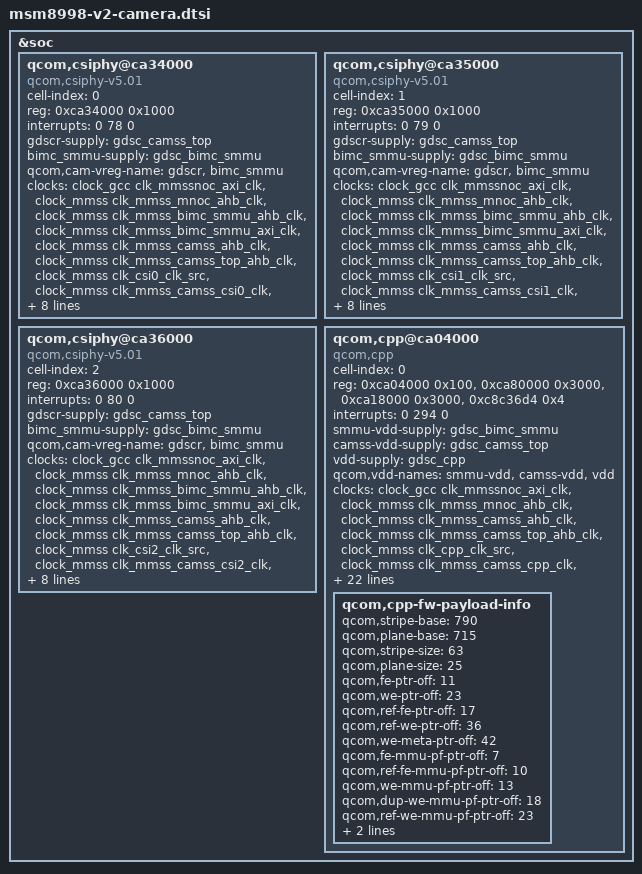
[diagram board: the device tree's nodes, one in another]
/*
 * Copyright (c) 2016, The Linux Foundation. All rights reserved.
 *
 * This program is free software; you can redistribute it and/or modify
 * it under the terms of the GNU General Public License version 2 and
 * only version 2 as published by the Free Software Foundation.
 *
 * This program is distributed in the hope that it will be useful,
 * but WITHOUT ANY WARRANTY; without even the implied warranty of
 * MERCHANTABILITY or FITNESS FOR A PARTICULAR PURPOSE.  See the
 * GNU General Public License for more details.
 */

&soc {
	qcom,csiphy@ca34000 {
		cell-index = <0>;
		compatible = "qcom,csiphy-v5.01", "qcom,csiphy";
		reg = <0xca34000 0x1000>;
		reg-names = "csiphy";
		interrupts = <0 78 0>;
		interrupt-names = "csiphy";
		gdscr-supply = <&gdsc_camss_top>;
		bimc_smmu-supply = <&gdsc_bimc_smmu>;
		qcom,cam-vreg-name = "gdscr", "bimc_smmu";
		clocks = <&clock_gcc clk_mmssnoc_axi_clk>,
			<&clock_mmss clk_mmss_mnoc_ahb_clk>,
			<&clock_mmss clk_mmss_bimc_smmu_ahb_clk>,
			<&clock_mmss clk_mmss_bimc_smmu_axi_clk>,
			<&clock_mmss clk_mmss_camss_ahb_clk>,
			<&clock_mmss clk_mmss_camss_top_ahb_clk>,
			<&clock_mmss clk_csi0_clk_src>,
			<&clock_mmss clk_mmss_camss_csi0_clk>,
			<&clock_mmss clk_mmss_camss_cphy_csid0_clk>,
			<&clock_mmss clk_csi0phytimer_clk_src>,
			<&clock_mmss clk_mmss_camss_csi0phytimer_clk>,
			<&clock_mmss clk_mmss_camss_ispif_ahb_clk>,
			<&clock_mmss clk_csiphy_clk_src>,
			<&clock_mmss clk_mmss_camss_csiphy0_clk>;
		clock-names = "mmssnoc_axi", "mnoc_ahb",
			"bmic_smmu_ahb", "bmic_smmu_axi",
			"camss_ahb_clk", "camss_top_ahb_clk",
			"csi_src_clk", "csi_clk", "cphy_csid_clk",
			"csiphy_timer_src_clk", "csiphy_timer_clk",
			"camss_ispif_ahb_clk", "csiphy_clk_src", "csiphy_clk";
		qcom,clock-rates = <0 0 0 0 0 0 256000000 0 0 200000000 0
			0 256000000 0>;
		status = "ok";
	};

	qcom,csiphy@ca35000 {
		cell-index = <1>;
		compatible = "qcom,csiphy-v5.01", "qcom,csiphy";
		reg = <0xca35000 0x1000>;
		reg-names = "csiphy";
		interrupts = <0 79 0>;
		interrupt-names = "csiphy";
		gdscr-supply = <&gdsc_camss_top>;
		bimc_smmu-supply = <&gdsc_bimc_smmu>;
		qcom,cam-vreg-name = "gdscr", "bimc_smmu";
		clocks = <&clock_gcc clk_mmssnoc_axi_clk>,
			<&clock_mmss clk_mmss_mnoc_ahb_clk>,
			<&clock_mmss clk_mmss_bimc_smmu_ahb_clk>,
			<&clock_mmss clk_mmss_bimc_smmu_axi_clk>,
			<&clock_mmss clk_mmss_camss_ahb_clk>,
			<&clock_mmss clk_mmss_camss_top_ahb_clk>,
			<&clock_mmss clk_csi1_clk_src>,
			<&clock_mmss clk_mmss_camss_csi1_clk>,
			<&clock_mmss clk_mmss_camss_cphy_csid1_clk>,
			<&clock_mmss clk_csi1phytimer_clk_src>,
			<&clock_mmss clk_mmss_camss_csi1phytimer_clk>,
			<&clock_mmss clk_mmss_camss_ispif_ahb_clk>,
			<&clock_mmss clk_csiphy_clk_src>,
			<&clock_mmss clk_mmss_camss_csiphy1_clk>;
		clock-names = "mmssnoc_axi", "mnoc_ahb",
			"bmic_smmu_ahb", "bmic_smmu_axi",
			"camss_ahb_clk", "camss_top_ahb_clk",
			"csi_src_clk", "csi_clk", "cphy_csid_clk",
			"csiphy_timer_src_clk", "csiphy_timer_clk",
			"camss_ispif_ahb_clk", "csiphy_clk_src", "csiphy_clk";
		qcom,clock-rates = <0 0 0 0 0 0 256000000 0 0 200000000 0
			0 256000000 0>;
		status = "ok";
	};

	qcom,csiphy@ca36000 {
		cell-index = <2>;
		compatible = "qcom,csiphy-v5.01", "qcom,csiphy";
		reg = <0xca36000 0x1000>;
		reg-names = "csiphy";
		interrupts = <0 80 0>;
		interrupt-names = "csiphy";
		gdscr-supply = <&gdsc_camss_top>;
		bimc_smmu-supply = <&gdsc_bimc_smmu>;
		qcom,cam-vreg-name = "gdscr", "bimc_smmu";
		clocks = <&clock_gcc clk_mmssnoc_axi_clk>,
			<&clock_mmss clk_mmss_mnoc_ahb_clk>,
			<&clock_mmss clk_mmss_bimc_smmu_ahb_clk>,
			<&clock_mmss clk_mmss_bimc_smmu_axi_clk>,
			<&clock_mmss clk_mmss_camss_ahb_clk>,
			<&clock_mmss clk_mmss_camss_top_ahb_clk>,
			<&clock_mmss clk_csi2_clk_src>,
			<&clock_mmss clk_mmss_camss_csi2_clk>,
			<&clock_mmss clk_mmss_camss_cphy_csid2_clk>,
			<&clock_mmss clk_csi2phytimer_clk_src>,
			<&clock_mmss clk_mmss_camss_csi2phytimer_clk>,
			<&clock_mmss clk_mmss_camss_ispif_ahb_clk>,
			<&clock_mmss clk_csiphy_clk_src>,
			<&clock_mmss clk_mmss_camss_csiphy2_clk>;
		clock-names = "mmssnoc_axi", "mnoc_ahb",
			"bmic_smmu_ahb", "bmic_smmu_axi",
			"camss_ahb_clk", "camss_top_ahb_clk",
			"csi_src_clk", "csi_clk", "cphy_csid_clk",
			"csiphy_timer_src_clk", "csiphy_timer_clk",
			"camss_ispif_ahb_clk", "csiphy_clk_src", "csiphy_clk";
		qcom,clock-rates = <0 0 0 0 0 0 256000000 0 0 200000000 0
			0 256000000 0>;
		status = "ok";
	};

	qcom,cpp@ca04000 {
		cell-index = <0>;
		compatible = "qcom,cpp";
		reg = <0xca04000 0x100>,
			<0xca80000 0x3000>,
			<0xca18000 0x3000>,
			<0xc8c36d4 0x4>;
		reg-names = "cpp", "cpp_vbif", "cpp_hw", "camss_cpp";
		interrupts = <0 294 0>;
		interrupt-names = "cpp";
		smmu-vdd-supply = <&gdsc_bimc_smmu>;
		camss-vdd-supply = <&gdsc_camss_top>;
		vdd-supply = <&gdsc_cpp>;
		qcom,vdd-names = "smmu-vdd", "camss-vdd", "vdd";
		clocks = <&clock_gcc clk_mmssnoc_axi_clk>,
			<&clock_mmss clk_mmss_mnoc_ahb_clk>,
			<&clock_mmss clk_mmss_camss_ahb_clk>,
			<&clock_mmss clk_mmss_camss_top_ahb_clk>,
			<&clock_mmss clk_cpp_clk_src>,
			<&clock_mmss clk_mmss_camss_cpp_clk>,
			<&clock_mmss clk_mmss_camss_cpp_ahb_clk>,
			<&clock_mmss clk_mmss_camss_cpp_axi_clk>,
			<&clock_mmss clk_mmss_camss_micro_ahb_clk>,
			<&clock_mmss clk_mmss_bimc_smmu_axi_clk>,
			<&clock_mmss clk_mmss_camss_cpp_vbif_ahb_clk>;
		clock-names = "mmssnoc_axi_clk",
			"mnoc_ahb_clk",
			"camss_ahb_clk", "camss_top_ahb_clk",
			"cpp_src_clk",
			"cpp_core_clk", "camss_cpp_ahb_clk",
			"camss_cpp_axi_clk", "micro_iface_clk",
			"mmss_smmu_axi_clk", "cpp_vbif_ahb_clk";
		qcom,clock-rates = <0 0 0 0 200000000 200000000 0 0 0 0 0>;
		qcom,min-clock-rate = <200000000>;
		qcom,bus-master = <1>;
		qcom,vbif-qos-setting = <0x20 0x10000000>,
			<0x24 0x10000000>,
			<0x28 0x10000000>,
			<0x2C 0x10000000>;
		status = "ok";
		qcom,msm-bus,name = "msm_camera_cpp";
		qcom,msm-bus,num-cases = <2>;
		qcom,msm-bus,num-paths = <1>;
		qcom,msm-bus,vectors-KBps =
			<106 512 0 0>,
			<106 512 0 0>;
		qcom,msm-bus-vector-dyn-vote;
		resets = <&clock_mmss CAMSS_MICRO_BCR>;
		reset-names = "micro_iface_reset";
		qcom,src-clock-rates = <100000000 200000000 384000000 404000000
			480000000 576000000 600000000>;
		qcom,micro-reset;
		qcom,cpp-fw-payload-info {
			qcom,stripe-base = <790>;
			qcom,plane-base = <715>;
			qcom,stripe-size = <63>;
			qcom,plane-size = <25>;
			qcom,fe-ptr-off = <11>;
			qcom,we-ptr-off = <23>;
			qcom,ref-fe-ptr-off = <17>;
			qcom,ref-we-ptr-off = <36>;
			qcom,we-meta-ptr-off = <42>;
			qcom,fe-mmu-pf-ptr-off = <7>;
			qcom,ref-fe-mmu-pf-ptr-off = <10>;
			qcom,we-mmu-pf-ptr-off = <13>;
			qcom,dup-we-mmu-pf-ptr-off = <18>;
			qcom,ref-we-mmu-pf-ptr-off = <23>;
			qcom,set-group-buffer-len = <135>;
			qcom,dup-frame-indicator-off = <70>;
		};
	};
};

